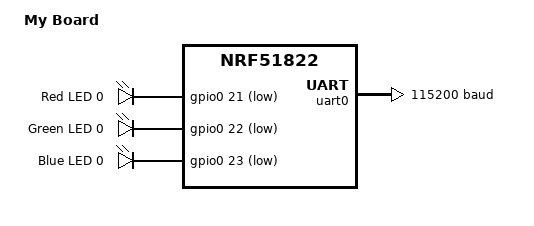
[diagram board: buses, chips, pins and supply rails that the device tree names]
/dts-v1/;

#include <nordic/nrf51822_qfac.dtsi>
#include "my_board-pinctrl.dtsi"

/ {
	model = "My Board";
	compatible = "iomico,my_board";

	aliases {
		led0 = &red_led;
		led1 = &green_led;
		led2 = &blue_led;
	};

	chosen {
		zephyr,console = &uart0;
		zephyr,sram = &sram0;
		zephyr,flash = &flash0;
		zephyr,code-partition = &slot0_partition;
	};

	leds {
		compatible = "gpio-leds";

		red_led: led_0 {
			gpios = <&gpio0 21 GPIO_ACTIVE_LOW>;
			label = "Red LED 0";
		};

		green_led: led_1 {
			gpios = <&gpio0 22 GPIO_ACTIVE_LOW>;
			label = "Green LED 0";
		};

		blue_led: led_2 {
			gpios = <&gpio0 23 GPIO_ACTIVE_LOW>;
			label = "Blue LED 0";
		};
	};
};

&gpiote {
	status = "okay";
};

&gpio0 {
	status = "okay";
};

&uart0 {
	current-speed = <115200>;
	status = "okay";
	pinctrl-0 = <&uart0_default>;
	pinctrl-1 = <&uart0_sleep>;
	pinctrl-names = "default", "sleep";
};

&flash0 {
	partitions {
		ranges;
		#address-cells = <1>;
		#size-cells = <1>;

		boot_partition: partition@0 {
			compatible = "zephyr,mapped-partition";
			label = "mcuboot";
			reg = <0x00000000 0x8000>;
		};

		slot0_partition: partition@8000 {
			compatible = "zephyr,mapped-partition";
			label = "image-0";
			reg = <0x00008000 0x1b000>;
		};

		slot1_partition: partition@23000 {
			compatible = "zephyr,mapped-partition";
			label = "image-1";
			reg = <0x00023000 0x1b000>;
		};

		storage_partition: partition@3e000 {
			compatible = "zephyr,mapped-partition";
			label = "storage";
			reg = <0x0003e000 0x00002000>;
		};
	};
};
